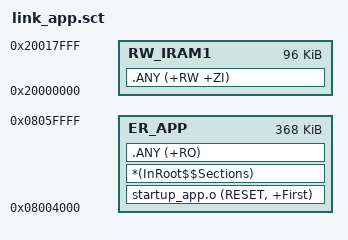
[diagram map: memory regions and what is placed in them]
; ============================================================================
; LUMOS-bootloader 测试 APP 的链接脚本
;
; 关键：整个镜像从 0x08004000 开始（BL_APP_BASE），
;       长度上限 368KB（= BL_APP_SIZE，S1-S6）。
;       一旦超了，armlink 会直接报 L6406E —— 不用等上板才发现。
; ============================================================================

LR_APP 0x08004000 0x0005C000 {
    ER_APP 0x08004000 0x0005C000 {
        startup_app.o (RESET, +First)
        *(InRoot$$Sections)
        .ANY (+RO)
    }

    RW_IRAM1 0x20000000 0x00018000 {
        .ANY (+RW +ZI)
    }
}
